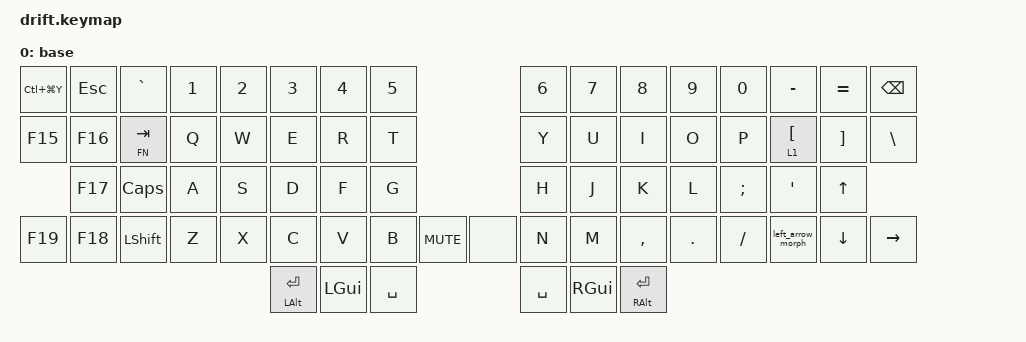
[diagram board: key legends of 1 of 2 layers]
// Copyright (c) 2025 Timception
// SPDX-License-Identifier: MIT

#define ZMK_POINTING_DEFAULT_MOVE_VAL 1500  // default: 600
#define ZMK_POINTING_DEFAULT_SCRL_VAL 120   // default: 10 - for encoder mouse-scroll to work

#include <dt-bindings/zmk/mouse.h>
#include <behaviors.dtsi>
#include <dt-bindings/zmk/keys.h>
#include <dt-bindings/zmk/pointing.h>

#define BASE 0
#define FN 1

/ {
    conditional_layers { compatible = "zmk,conditional-layers"; };

    behaviors {
        enc_scroll: enc_scroll {
            compatible = "zmk,behavior-sensor-rotate-var";
            #sensor-binding-cells = <2>;
            bindings = <&msc>, <&msc>;

            tap-ms = <20>;
        };

        left_arrow_holdtap: left_arrow_holdtap {
            compatible = "zmk,behavior-hold-tap";
            label = "LEFT_ARROW_HOLDTAP";
            bindings = <&kp>, <&kp>;

            #binding-cells = <2>;
            tapping-term-ms = <150>;
            flavor = "tap-unless-interrupted";
            hold-trigger-key-positions = <0 1 2 3 4 5 6 7 8 9 10 11 12 13 14 15 16 17 18 29 30 32 33 34 35 36 37 38 39 40 41 42 43 44 19 20 21 22 23 24 25 26 27 28 29 30 31 46 47 48 49 50 52 53 54 55 56 57 59 60 64 69 34 35 36 37 38 39 40 41 49 50 51 52 53 54 55 56 57 58 64 65 66 67 68 69>;
        };

        left_arrow_morph: left_arrow_morph {
            compatible = "zmk,behavior-mod-morph";
            label = "LEFT_ARROW_MORPH";
            bindings = <&left_arrow_holdtap RIGHT_SHIFT LEFT>, <&kp LEFT>;

            #binding-cells = <0>;
            mods = <(MOD_LCTL|MOD_LSFT|MOD_LALT|MOD_LGUI|MOD_RCTL|MOD_RALT|MOD_RGUI)>;
            keep-mods = <(MOD_LCTL|MOD_LSFT|MOD_LALT|MOD_LGUI|MOD_RCTL|MOD_RALT|MOD_RGUI)>;
        };

        cmd_on: cmd_on {
            compatible = "zmk,behavior-macro";
            #binding-cells = <0>;
            bindings = <&macro_press>, <&kp LGUI>;
        };

        cmd_off: cmd_off {
            compatible = "zmk,behavior-macro";
            #binding-cells = <0>;
            bindings = <&macro_release>, <&kp LGUI>;
        };

        swapper_next: swapper_next {
            compatible = "zmk,behavior-tri-state";
            label = "SWAPPER_NEXT";
            #binding-cells = <0>;
            bindings = <&cmd_on>, <&kp TAB>, <&cmd_off>;

            timeout-ms = <3000>;
        };

        swapper_prev: swapper_prev {
            compatible = "zmk,behavior-tri-state";
            label = "SWAPPER_PREV";
            #binding-cells = <0>;
            bindings = <&cmd_on>, <&kp LS(TAB)>, <&cmd_off>;

            timeout-ms = <3000>;
        };

        enc_tabswitch: enc_tabswitch {
            compatible = "zmk,behavior-sensor-rotate-var";
            #sensor-binding-cells = <2>;
            bindings = <&swapper_prev>, <&swapper_next>;
        };
    };

    macros {
    };

    keymap {
        compatible = "zmk,keymap";

        base {
            bindings = <
&kp LC(LG(Y))  &kp ESC  &kp GRAVE   &kp N1  &kp N2  &kp N3          &kp N4    &kp N5                        &kp N6     &kp N7    &kp N8          &kp N9   &kp N0    &kp MINUS          &kp EQUAL  &kp BSPC
&kp F15        &kp F16  &lt FN TAB  &kp Q   &kp W   &kp E           &kp R     &kp T                         &kp Y      &kp U     &kp I           &kp O    &kp P     &lt 1 LBKT         &kp RBKT   &kp BSLH
               &kp F17  &kp CAPS    &kp A   &kp S   &kp D           &kp F     &kp G                         &kp H      &kp J     &kp K           &kp L    &kp SEMI  &kp APOS           &kp UP
&kp F19        &kp F18  &kp LSHFT   &kp Z   &kp X   &kp C           &kp V     &kp B      &kp K_MUTE  &none  &kp N      &kp M     &kp COMMA       &kp DOT  &kp FSLH  &left_arrow_morph  &kp DOWN   &kp RIGHT
                                                    &mt LALT ENTER  &kp LGUI  &kp SPACE                     &kp SPACE  &kp RGUI  &mt RALT ENTER
            >;

            sensor-bindings =
                <&inc_dec_kp C_VOL_DN C_VOL_UP>,
                <&enc_tabswitch 0 0>;
        };

        fn {
            label = "fn";
            bindings = <
&trans  &trans  &trans  &kp F1                &kp F2                &kp F3          &kp F4   &kp F5                              &kp F6          &kp F7         &kp F8            &kp F9              &kp F10     &kp F11       &kp F12       &kp DEL
&trans  &trans  &trans  &kp C_BRIGHTNESS_DEC  &kp C_BRIGHTNESS_INC  &kp LC(LG(UP))  &kp F14  &kp LC(LS(LG(N4)))                  &kp LS(LG(N4))  &kp C_REWIND   &kp C_PLAY_PAUSE  &kp C_FAST_FORWARD  &kp K_MUTE  &kp C_VOL_DN  &kp C_VOL_UP  &trans
        &trans  &trans  &trans                &trans                &trans          &trans   &trans                              &kp HOME        &kp PAGE_DOWN  &kp PAGE_UP       &kp END             &trans      &trans        &trans
&trans  &trans  &trans  &trans                &trans                &trans          &trans   &trans              &trans  &trans  &trans          &trans         &trans            &trans              &trans      &trans        &trans        &trans
            >;

            sensor-bindings =
                <&inc_dec_kp C_VOL_DN C_VOL_UP>,
                <&enc_tabswitch 0 0>;
        };
    };
};
